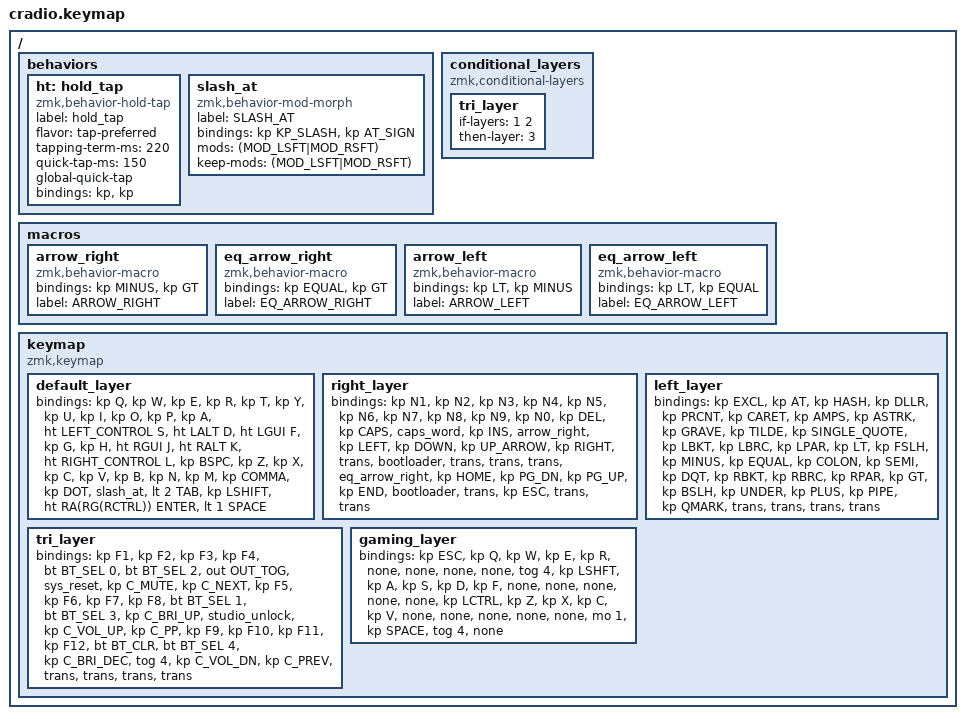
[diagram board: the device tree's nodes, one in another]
// Copyright (c) 2022 The ZMK Contributors
// SPDX-License-Identifier: MIT

#include <behaviors.dtsi>
#include <dt-bindings/zmk/bt.h>
#include <dt-bindings/zmk/keys.h>
#include <dt-bindings/zmk/outputs.h>

/ {
    behaviors {
        ht: hold_tap {
            label = "hold_tap";
            compatible = "zmk,behavior-hold-tap";
            #binding-cells = <2>;
            flavor = "tap-preferred";
            tapping-term-ms = <220>;
            quick-tap-ms = <150>;
            global-quick-tap;
            bindings = <&kp>, <&kp>;
        };

        slash_at: slash_at {
            compatible = "zmk,behavior-mod-morph";
            label = "SLASH_AT";
            bindings = <&kp KP_SLASH>, <&kp AT_SIGN>;

            #binding-cells = <0>;
            mods = <(MOD_LSFT|MOD_RSFT)>;
            keep-mods = <(MOD_LSFT|MOD_RSFT)>;
        };
    };

    conditional_layers {
        compatible = "zmk,conditional-layers";

        tri_layer {
            if-layers = <1 2>;
            then-layer = <3>;
        };
    };

    macros {
        arrow_right: arrow_right {
            compatible = "zmk,behavior-macro";
            #binding-cells = <0>;
            bindings = <&kp MINUS &kp GT>;
            label = "ARROW_RIGHT";
        };

        eq_arrow_right: eq_arrow_right {
            compatible = "zmk,behavior-macro";
            #binding-cells = <0>;
            bindings = <&kp EQUAL &kp GT>;
            label = "EQ_ARROW_RIGHT";
        };

        arrow_left: arrow_left {
            compatible = "zmk,behavior-macro";
            #binding-cells = <0>;
            bindings = <&kp LT &kp MINUS>;
            label = "ARROW_LEFT";
        };

        eq_arrow_left: eq_arrow_left {
            compatible = "zmk,behavior-macro";
            #binding-cells = <0>;
            bindings = <&kp LT &kp EQUAL>;
            label = "EQ_ARROW_LEFT";
        };
    };

    keymap {
        compatible = "zmk,keymap";

        default_layer {
            bindings = <
&kp Q  &kp W  &kp E  &kp R  &kp T  &kp Y  &kp U  &kp I  &kp O  &kp P  &kp A  &ht LEFT_CONTROL S  &ht LALT D  &ht LGUI F  &kp G  &kp H  &ht RGUI J  &ht RALT K  &ht RIGHT_CONTROL L  &kp BSPC  &kp Z  &kp X  &kp C  &kp V  &kp B  &kp N  &kp M  &kp COMMA  &kp DOT  &slash_at  &lt 2 TAB  &kp LSHIFT  &ht RA(RG(RCTRL)) ENTER  &lt 1 SPACE
            >;
        };

        right_layer {
            bindings = <
&kp N1  &kp N2  &kp N3  &kp N4  &kp N5  &kp N6  &kp N7  &kp N8  &kp N9  &kp N0  &kp DEL  &kp CAPS  &caps_word  &kp INS  &arrow_right  &kp LEFT  &kp DOWN  &kp UP_ARROW  &kp RIGHT  &trans  &bootloader  &trans  &trans  &trans  &eq_arrow_right  &kp HOME  &kp PG_DN  &kp PG_UP  &kp END  &bootloader  &trans  &kp ESC  &trans  &trans
            >;
        };

        left_layer {
            bindings = <
&kp EXCL  &kp AT  &kp HASH  &kp DLLR  &kp PRCNT  &kp CARET  &kp AMPS  &kp ASTRK  &kp GRAVE  &kp TILDE  &kp SINGLE_QUOTE  &kp LBKT  &kp LBRC  &kp LPAR  &kp LT  &kp FSLH  &kp MINUS  &kp EQUAL  &kp COLON  &kp SEMI  &kp DQT  &kp RBKT  &kp RBRC  &kp RPAR  &kp GT  &kp BSLH  &kp UNDER  &kp PLUS  &kp PIPE  &kp QMARK  &trans  &trans  &trans  &trans
            >;
        };

        tri_layer {
            bindings = <
&kp F1  &kp F2  &kp F3  &kp F4  &bt BT_SEL 0  &bt BT_SEL 2  &out OUT_TOG  &sys_reset  &kp C_MUTE  &kp C_NEXT  &kp F5  &kp F6  &kp F7  &kp F8  &bt BT_SEL 1  &bt BT_SEL 3  &kp C_BRI_UP  &studio_unlock  &kp C_VOL_UP  &kp C_PP  &kp F9  &kp F10  &kp F11  &kp F12  &bt BT_CLR  &bt BT_SEL 4  &kp C_BRI_DEC  &tog 4  &kp C_VOL_DN  &kp C_PREV  &trans  &trans  &trans  &trans
            >;
        };

        gaming_layer {
            bindings = <
&kp ESC  &kp Q  &kp W  &kp E  &kp R  &none  &none  &none  &none  &tog 4  &kp LSHFT  &kp A  &kp S  &kp D  &kp F  &none  &none  &none  &none  &none  &kp LCTRL  &kp Z  &kp X  &kp C  &kp V  &none  &none  &none  &none  &none  &mo 1  &kp SPACE  &tog 4  &none
            >;
        };

        /* colemak_dh_layer { */
        /*       bindings = < */
        /*   //╭──────────┬──────────┬──────────┬──────────┬──────────╮ ╭──────────┬──────────┬──────────┬──────────┬──────────╮ */
        /*   //│        Q │        W │        F │        P │        B │ │        J │        L │        U │        Y │        ; │ */
        /*       &kp Q    &kp W    &kp F    &kp P    &kp B                   &kp J    &kp L    &kp U    &kp Y         &kp SEMI  */
        /*   //├──────────┼──────────┼──────────┼──────────┼──────────┤ ├──────────┼──────────┼──────────┼──────────┼──────────┤ */
        /*   //│        A │        R │        S │        T │        G │ │        M │        N │        E │        I │        O │ */
        /*       &kp A        &kp R     HRML(S,          T)      &kp G       &kp M    HRMR(N,         E)       &kp I    &kp O */
        /*   //├──────────┼──────────┼──────────┼──────────┼──────────┤ ├──────────┼──────────┼──────────┼──────────┼──────────┤ */
        /*   //│        Z │        X │        C │        D │        V │ │        K │        H │      , < │      . > │        / │ */
        /*       &kp Z        &kp X      &kp C       &kp D      &kp V         &kp K      &kp H    &kp COMMA &kp DOT   &kp FSLH */
        /*   //╰──────────┴──────────┴──────────┼──────────┼──────────┤ ├──────────┼──────────┼──────────┴──────────┴──────────╯ */
        /*                                     &lt LEF TAB  &mt LSHIFT ENTER   &mt RCTRL BSPC   &lt RIG SPACE */
        /*   //                                 ╰──────────┴──────────╯         ╰──────────┴──────────╯ */
        /*       >; */
        /* }; */
    };
};
